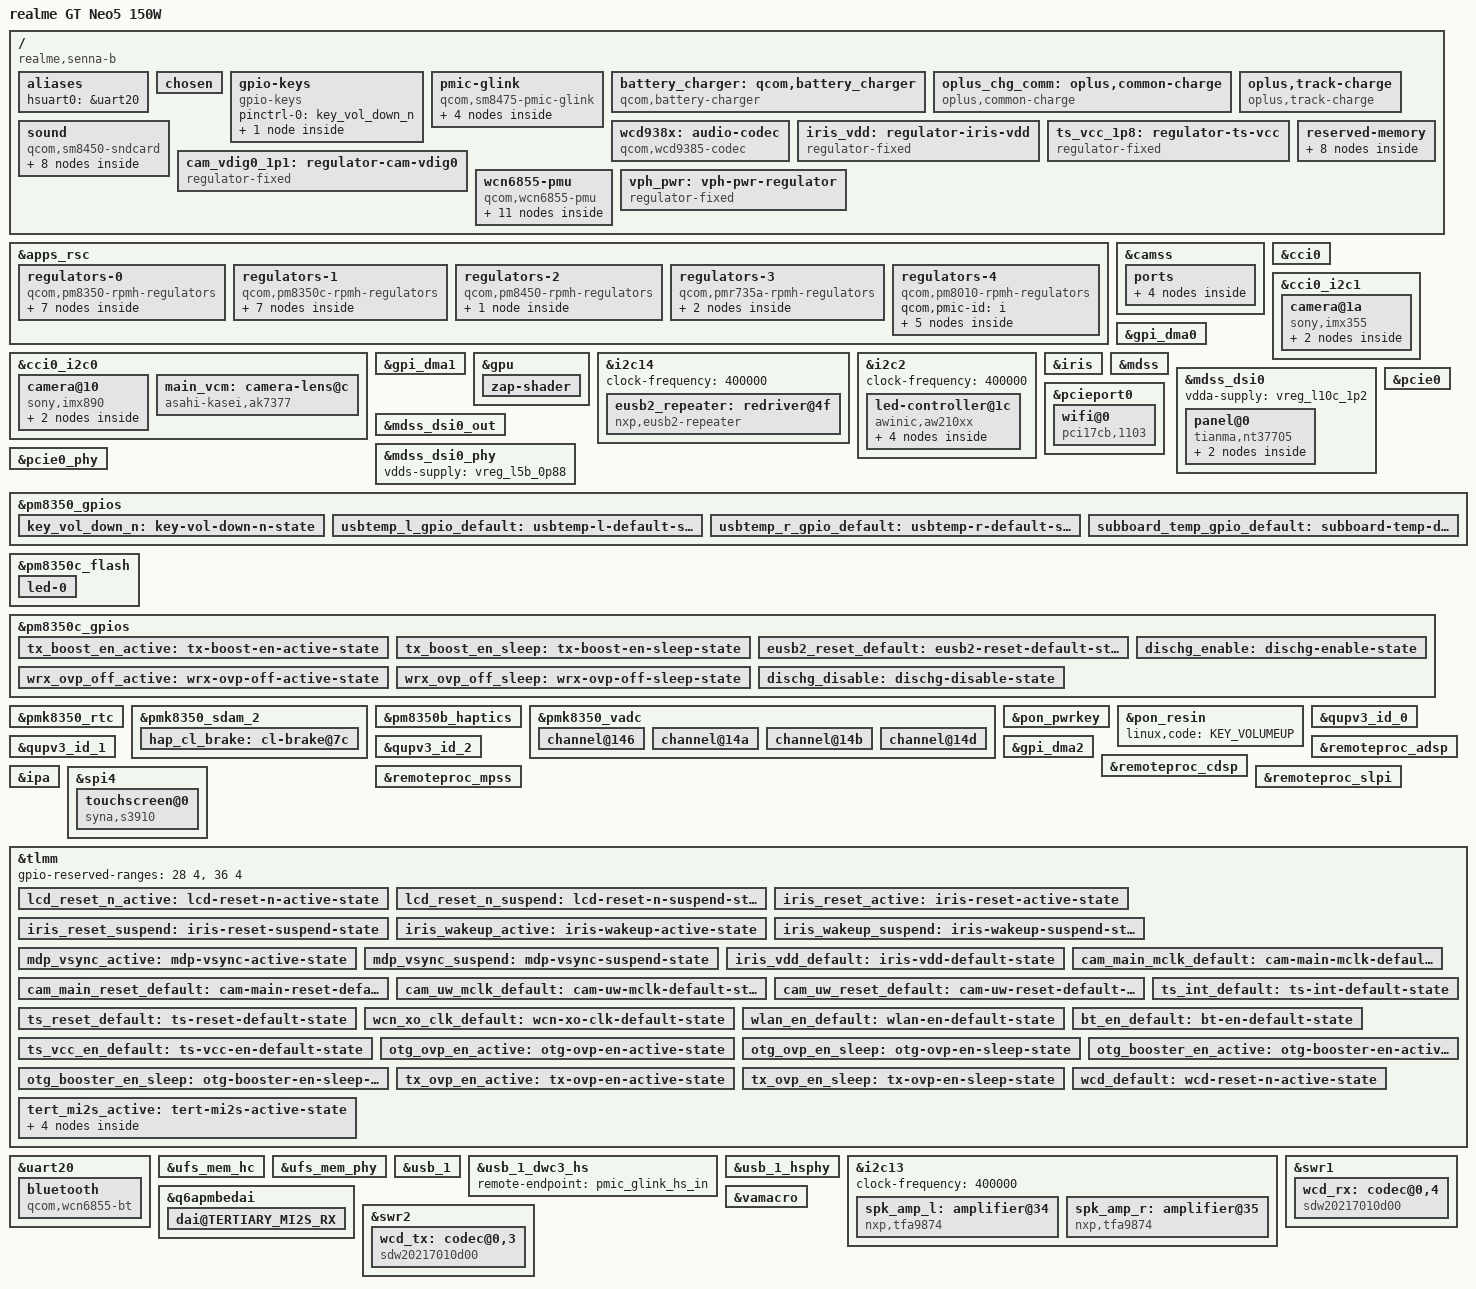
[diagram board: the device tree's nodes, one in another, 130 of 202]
// SPDX-License-Identifier: GPL-2.0-only
/*
 * realme GT Neo5 150W (senna, project 22624)
 *
 * Copyright (c) 2024, The Linux Foundation. All rights reserved.
 * Copyright (c) 2024, Jens Reidel <adrian@travitia.xyz>
 *
 * Based on the senna-b device tree by Marohinmark
 * (github.com/marohinmark/linux-sm8450, branch next). Values (regulators,
 * GPIOs, reserved memory) were checked against the device tree of the
 * running downstream kernel (/sys/firmware/fdt), not guessed. Structure
 * follows sm8475-nothing-pong.dts.
 */
/dts-v1/;

#include <dt-bindings/gpio/gpio.h>
#include <dt-bindings/iio/qcom,spmi-adc7-pm8350.h>
#include <dt-bindings/interrupt-controller/irq.h>
#include <dt-bindings/input/linux-event-codes.h>
#include <dt-bindings/leds/common.h>
#include <dt-bindings/media/video-interfaces.h>
#include <dt-bindings/pinctrl/qcom,pmic-gpio.h>
#include <dt-bindings/regulator/qcom,rpmh-regulator.h>

#include "sm8475.dtsi"
#include "pm8350.dtsi"
#include "pm8350b.dtsi"
#include "pm8350c.dtsi"
#include "pm8450.dtsi"
#include "pmk8350.dtsi"
#include "pmr735a.dtsi"

/delete-node/ &adsp_mem;
/delete-node/ &rmtfs_mem;
/delete-node/ &slpi_mem;
/delete-node/ &video_mem;

/ {
	model = "realme GT Neo5 150W";
	compatible = "realme,senna-b", "qcom,sm8475";
	chassis-type = "handset";

	/*
	 * Booted WITHOUT a valid dtbo: ABL then needs an exact board match
	 * (platform_dt_absolute_match): MTP (0x08), version 1.0, subtype 0,
	 * DDR bits 0 (RAM > 4 GB). Measured on Android: hw_platform=MTP,
	 * platform_version=65536, platform_subtype_id=0, soc_id=530.
	 * No qcom,pmic-id on purpose (ABL parses it in a different layout).
	 */
	qcom,msm-id = <0x212 0x10000>, <0x21c 0x10000>;
	qcom,board-id = <0x10008 0>;

	aliases {
		hsuart0 = &uart20;
	};

	chosen {
		#address-cells = <2>;
		#size-cells = <2>;
		ranges;
	};

	gpio-keys {
		compatible = "gpio-keys";

		pinctrl-0 = <&key_vol_down_n>;
		pinctrl-names = "default";

		key-volume-down {
			label = "Volume Down";
			linux,code = <KEY_VOLUMEDOWN>;
			gpios = <&pm8350_gpios 6 GPIO_ACTIVE_LOW>;
			debounce-interval = <15>;
			linux,can-disable;
			wakeup-source;
		};
	};

	/*
	 * Battery/charger and the USB-C port controller run on the ADSP
	 * (downstream qcom,pmic_glink with qcom,battery_charger, qcom,ucsi and
	 * qcom,altmode). UCSI reports the data role of the port and drives the
	 * DWC3 role switch. USB 2.0 only: the SuperSpeed lanes are not wired up.
	 */
	pmic-glink {
		compatible = "qcom,sm8475-pmic-glink",
			     "qcom,sm8450-pmic-glink",
			     "qcom,pmic-glink";
		#address-cells = <1>;
		#size-cells = <0>;

		connector@0 {
			compatible = "usb-c-connector";
			reg = <0>;
			power-role = "dual";
			data-role = "dual";

			ports {
				#address-cells = <1>;
				#size-cells = <0>;

				port@0 {
					reg = <0>;

					pmic_glink_hs_in: endpoint {
						remote-endpoint = <&usb_1_dwc3_hs>;
					};
				};
			};
		};
	};

	/*
	 * OPLUS charger (oplus_chg v1, out of tree). The OPLUS ADSP charger firmware
	 * keeps charging disabled (BATT_CHG_EN 0, USB ICL 0) until this AP driver
	 * enables it, so it replaces qcom_battmgr on the same pmic_glink service.
	 * Values: oplus-chg-22624.dtsi, identical in the running 5.10 and 6.6 device
	 * trees. Not ported: VOOC/PPS (oplus,adsp-voocphy, the sc8571 charge pumps
	 * and the pps_* strategies) and the nu1619 wireless receiver.
	 */
	battery_charger: qcom,battery_charger {
		compatible = "qcom,battery-charger";
		qcom,thermal-mitigation = <3000000 1500000 1000000 500000>;
		qcom,wireless-fw-name = "idt9415.bin";
		/* OPLUS_CHG_IC_BUCK, first instance */
		oplus,ic_type = <0>;
		oplus,ic_index = <0>;

		oplus,chg_ops = "plat-pmic";
		qcom,smart_charging_screenoff;
		/*
		 * Downstream: <1> (VOOC runs on the ADSP). Off until the AP-side
		 * oplus,adsp-voocphy driver and the sc8571 pumps are ported: with <1>
		 * the driver enables the ADSP VOOC engine without anything on the AP
		 * supervising it.
		 */
		qcom,voocphy_support = <0>;
		qcom,input_current_charger_ma = <2000>;
		qcom,pd_input_current_charger_ma = <2000>;
		qcom,qc_input_current_charger_ma = <2000>;
		qcom,input_current_usb_ma = <500>;
		qcom,input_current_cdp_ma = <1500>;
		qcom,input_current_led_ma = <1200>;
		qcom,input_current_led_ma_high = <1200>;
		qcom,input_current_led_ma_warm = <1500>;
		qcom,input_current_led_ma_normal = <2000>;
		qcom,led_warm_bat_decidegc = <350>;
		qcom,led_high_bat_decidegc = <370>;
		qcom,input_current_camera_ma = <1200>;
		qcom,input_current_vooc_led_ma_high = <2200>;
		qcom,input_current_vooc_led_ma_warm = <3200>;
		qcom,input_current_vooc_led_ma_normal = <3600>;
		qcom,input_current_vooc_ma_normal = <3600>;
		qcom,vooc_temp_bat_normal_decidegc = <350>;
		qcom,input_current_vooc_ma_warm = <3200>;
		qcom,vooc_temp_bat_warm_decidegc = <370>;
		qcom,input_current_vooc_ma_high = <2200>;
		qcom,vooc_temp_bat_hot_decidegc = <440>;
		qcom,charger_current_vooc_ma_normal = <1800>;
		qcom,chg_ctrl_by_calling;
		qcom,input_current_calling_ma = <1500>;
		qcom,overtemp_bat_decidegc = <350>;
		qcom,iterm_disabled = <0>;
		qcom,iterm_ma = <132>;
		qcom,recharge-mv = <100>;
		qcom,batt_capacity_mah = <5000>;
		qcom,removed_bat_decidegc = <390>;
		qcom,cold_bat_decidegc = <200>;
		qcom,temp_cold_vfloat_mv = <4435>;
		qcom,temp_cold_fastchg_current_ma_high = <350>;
		qcom,temp_cold_fastchg_current_ma_low = <200>;
		qcom,temp_cold_fastchg_current_ma = <200>;
		qcom,freeze_bat_decidegc = <100>;
		qcom,temp_freeze_fastchg_current_ma_high = <950>;
		qcom,temp_freeze_fastchg_current_ma_low = <350>;
		qcom,temp_freeze_fastchg_current_ma = <350>;
		qcom,little_cold_bat_decidegc = <0>;
		qcom,temp_little_cold_vfloat_mv = <4435>;
		qcom,temp_little_cold_fastchg_current_ma_high = <1100>;
		qcom,temp_little_cold_fastchg_current_ma_low = <1100>;
		qcom,temp_little_cold_fastchg_current_ma = <1100>;
		qcom,pd_temp_little_cold_fastchg_current_ma_high = <2000>;
		qcom,pd_temp_little_cold_fastchg_current_ma_low = <1500>;
		qcom,qc_temp_little_cold_fastchg_current_ma_high = <2000>;
		qcom,qc_temp_little_cold_fastchg_current_ma_low = <1500>;
		qcom,cool_bat_decidegc = <50>;
		qcom,temp_cool_vfloat_mv = <4435>;
		qcom,temp_cool_fastchg_current_ma_high = <1100>;
		qcom,temp_cool_fastchg_current_ma_low = <1100>;
		qcom,pd_temp_cool_fastchg_current_ma_high = <2000>;
		qcom,pd_temp_cool_fastchg_current_ma_low = <2000>;
		qcom,qc_temp_cool_fastchg_current_ma_high = <2000>;
		qcom,qc_temp_cool_fastchg_current_ma_low = <2000>;
		qcom,little_cool_bat_decidegc = <120>;
		qcom,temp_little_cool_vfloat_mv = <4435>;
		qcom,temp_little_cool_fastchg_current_ma = <1100>;
		qcom,pd_temp_little_cool_fastchg_current_ma = <2000>;
		qcom,qc_temp_little_cool_fastchg_current_ma = <2000>;
		qcom,normal_bat_decidegc = <160>;
		qcom,temp_normal_fastchg_current_ma = <1100>;
		qcom,temp_normal_vfloat_mv = <4435>;
		qcom,pd_temp_normal_fastchg_current_ma = <2000>;
		qcom,qc_temp_normal_fastchg_current_ma = <2000>;
		qcom,warm_bat_decidegc = <450>;
		qcom,temp_warm_vfloat_mv = <4130>;
		qcom,temp_warm_fastchg_current_ma = <1100>;
		qcom,pd_temp_warm_fastchg_current_ma = <1100>;
		qcom,qc_temp_warm_fastchg_current_ma = <1100>;
		qcom,temp_warm_fastchg_current_ma_led_on = <500>;
		qcom,hot_bat_decidegc = <530>;
		qcom,non_standard_vfloat_mv = <3980>;
		qcom,non_standard_fastchg_current_ma = <512>;
		qcom,short_c_bat_cv_mv = <4330>;
		qcom,short_c_bat_vfloat_mv = <3800>;
		qcom,short_c_bat_fastchg_current_ma = <512>;
		qcom,cold_vfloat_sw_limit = <4385>;
		qcom,little_cold_vfloat_sw_limit = <4385>;
		qcom,cool_vfloat_sw_limit = <4385>;
		qcom,little_cool_vfloat_sw_limit = <4385>;
		qcom,normal_vfloat_sw_limit = <4385>;
		qcom,warm_vfloat_sw_limit = <4080>;
		qcom,non_standard_vfloat_sw_limit = <3930>;
		qcom,short_c_bat_vfloat_sw_limit = <3750>;
		qcom,max_chg_time_sec = <69840>;
		qcom,charger_hv_thr = <9900>;
		qcom,charger_recv_thr = <9500>;
		qcom,charger_lv_thr = <3400>;
		qcom,vbatt_full_thr = <4435>;
		qcom,vbatt_hv_thr = <4600>;
		qcom,vfloat_step_mv = <8>;
		qcom,non_standard_vfloat_over_sw_limit = <3990>;
		qcom,cold_vfloat_over_sw_limit = <4445>;
		qcom,little_cold_vfloat_over_sw_limit = <4445>;
		qcom,cool_vfloat_over_sw_limit = <4445>;
		qcom,little_cool_vfloat_over_sw_limit = <4445>;
		qcom,normal_vfloat_over_sw_limit = <4445>;
		qcom,warm_vfloat_over_sw_limit = <4140>;
		qcom,vooc-high-temp = <520>;
		qcom,vooc-normal-high-temp = <430>;
		qcom,vooc-warm-allow-soc = <50>;
		qcom,vooc_batt_over_high_temp = <510>;
		qcom,vooc-warm-allow-vol = <4130>;
		qcom,vbatt_power_off = <3300>;
		qcom,vbatt_soc_1 = <3310>;
		qcom,vooc_project = <9>;
		qcom,vbatt_num = <2>;
		qcom,ffc_support;
		qcom,dual_ffc;
		recharge_after_full;
		qcom,nightstandby_support;
		qcom,normal_vterm_hw_inc = <18>;
		qcom,non_normal_vterm_hw_inc = <18>;
		qcom,ff1_normal_fastchg_ma = <550>;
		qcom,ff1_warm_fastchg_ma = <550>;
		qcom,ffc2_normal_fastchg_ma = <350>;
		qcom,ffc2_temp_warm_decidegc = <350>;
		qcom,ffc2_warm_fastchg_ma = <350>;
		qcom,ffc2_temp_high_decidegc = <400>;
		qcom,ffc2_temp_low_decidegc = <120>;
		qcom,ff1_exit_step_ma = <150>;
		qcom,ff1_warm_exit_step_ma = <150>;
		qcom,ffc2_exit_step_ma = <150>;
		qcom,ffc2_warm_exit_step_ma = <150>;
		qcom,ffc_normal_vfloat_sw_limit = <4445>;
		qcom,ffc_temp_normal_vfloat_mv = <4500>;
		qcom,ffc1_temp_normal_vfloat_mv = <4500>;
		qcom,ffc1_normal_vfloat_over_sw_limit = <4500>;
		qcom,ffc_normal_vfloat_over_sw_limit = <4500>;
		qcom,ffc_warm_vfloat_sw_limit = <4445>;
		qcom,ffc_temp_warm_vfloat_mv = <4500>;
		qcom,ffc_warm_vfloat_over_sw_limit = <4500>;
		qcom,ffc2_normal_vfloat_sw_limit = <4440>;
		qcom,ffc2_temp_normal_vfloat_mv = <4500>;
		qcom,ffc2_normal_vfloat_over_sw_limit = <4500>;
		qcom,ffc2_warm_vfloat_sw_limit = <4435>;
		qcom,ffc2_temp_warm_vfloat_mv = <4500>;
		qcom,ffc2_warm_vfloat_over_sw_limit = <4500>;
		qcom,usbtemp_batt_temp_low = <50>;
		qcom,usbtemp_batt_temp_high = <50>;
		qcom,usbtemp_ntc_temp_low = <57>;
		qcom,usbtemp_ntc_temp_high = <69>;
		qcom,usbtemp_temp_gap_low_with_batt_temp = <7>;
		qcom,usbtemp_temp_gap_high_with_batt_temp = <12>;
		qcom,usbtemp_temp_gap_low_without_batt_temp = <12>;
		qcom,usbtemp_temp_gap_high_without_batt_temp = <24>;
		qcom.usbtemp_rise_fast_temp_low = <3>;
		qcom.usbtemp_rise_fast_temp_high = <3>;
		qcom.usbtemp_rise_fast_temp_count_low = <30>;
		qcom.usbtemp_rise_fast_temp_count_high = <20>;
		qcom,usbtemp_cool_down_ntc_low = <54>;
		qcom,usbtemp_cool_down_ntc_high = <65>;
		qcom,usbtemp_cool_down_gap_low = <12>;
		qcom,usbtemp_cool_down_gap_high = <20>;
		qcom,usbtemp_cool_down_recover_ntc_low = <48>;
		qcom,usbtemp_cool_down_recover_ntc_high = <60>;
		qcom,usbtemp_cool_down_recover_gap_low = <6>;
		qcom,usbtemp_cool_down_recover_gap_high = <15>;
		qcom,default_iterm_ma = <132>;
		qcom,default_temp_normal_fastchg_current_ma = <1100>;
		qcom,default_normal_vfloat_sw_limit = <4385>;
		qcom,default_temp_normal_vfloat_mv = <4435>;
		qcom,default_normal_vfloat_over_sw_limit = <4445>;
		qcom,default_temp_little_cool_fastchg_current_ma = <1100>;
		qcom,default_little_cool_vfloat_sw_limit = <4385>;
		qcom,default_temp_little_cool_vfloat_mv = <4435>;
		qcom,default_little_cool_vfloat_over_sw_limit = <4445>;
		qcom,fg_info_package_read_support;
		qcom,check_batt_full_by_sw;
		qcom,external_gauge;
		qcom,chg_ctrl_by_lcd;
		qcom,chg_ctrl_by_vooc;
		qcom,chg_ctrl_by_camera;
		qcom,sw_vfloat_over_protect_enable;
		qcom,usbtemp_batttemp_gap = <12>;
		qcom,usbtemp_change_gap;
		oplus,smooth_switch_v2;
		oplus,reserve_chg_soc = <2>;
		oplus,reserve_dis_soc = <2>;
		qcom,smart_chg_soh_support;
		oplus,aging_ffc_version = <1>;
		oplus,quick_mode_gain_support;
		qcom,support_usbtemp_protect_v2;
		qcom,vbatt_pdqc_to_9v_thr = <5000>;
		qcom,vooc_show_ui_soc_decimal;
		qcom,ui_soc_decimal_speedmin = <20>;
		qcom,otg_scheme = <0>;
		qcom,otg_boost_src = <0>;

		qcom,dischg-gpio = <&pm8350c_gpios 9 GPIO_ACTIVE_HIGH>;
		qcom,otg-booster-en-gpio = <&tlmm 64 GPIO_ACTIVE_HIGH>;
		qcom,otg-ovp-en-gpio = <&tlmm 57 GPIO_ACTIVE_HIGH>;
		qcom,tx_ovp_en-gpio = <&tlmm 126 GPIO_ACTIVE_HIGH>;
		qcom,tx_boost_en-gpio = <&pm8350c_gpios 4 GPIO_ACTIVE_HIGH>;
		qcom,wrx_ovp_off-gpio = <&pm8350c_gpios 8 GPIO_ACTIVE_HIGH>;

		io-channels = <&pmk8350_vadc PM8350_ADC7_GPIO1_100K_PU(1)>,
			      <&pmk8350_vadc PM8350_ADC7_GPIO2_100K_PU(1)>,
			      <&pmk8350_vadc PM8350_ADC7_GPIO4_100K_PU(1)>;
		io-channel-names = "usb_temp_adc",
				   "usb_supplementary_temp_adc",
				   "subboard_temp_adc";

		/* the driver selects these by name, none of them is "default" */
		pinctrl-0 = <&dischg_enable>;
		pinctrl-1 = <&dischg_disable>;
		pinctrl-2 = <&otg_booster_en_active>;
		pinctrl-3 = <&otg_booster_en_sleep>;
		pinctrl-4 = <&otg_ovp_en_active>;
		pinctrl-5 = <&otg_ovp_en_sleep>;
		pinctrl-6 = <&usbtemp_l_gpio_default>;
		pinctrl-7 = <&usbtemp_r_gpio_default>;
		pinctrl-8 = <&tx_ovp_en_active>;
		pinctrl-9 = <&tx_ovp_en_sleep>;
		pinctrl-10 = <&tx_boost_en_active>;
		pinctrl-11 = <&tx_boost_en_sleep>;
		pinctrl-12 = <&wrx_ovp_off_active>;
		pinctrl-13 = <&wrx_ovp_off_sleep>;
		pinctrl-14 = <&subboard_temp_gpio_default>;
		pinctrl-names = "dischg_enable", "dischg_disable",
				"otg_booster_en_active", "otg_booster_en_sleep",
				"otg_ovp_en_active", "otg_ovp_en_sleep",
				"usbtemp_l_gpio_default", "usbtemp_r_gpio_default",
				"tx_ovp_en_active", "tx_ovp_en_sleep",
				"tx_boost_en_active", "tx_boost_en_sleep",
				"wrx_ovp_off_active", "wrx_ovp_off_sleep",
				"subboard_temp_gpio_default";
	};

	oplus_chg_comm: oplus,common-charge {
		compatible = "oplus,common-charge";

		io-channels = <&pmk8350_vadc PM8350_ADC7_AMUX_THM3_100K_PU(1)>;
		io-channel-names = "pm8350_hot_pocket_therm";
		oplus,skin_temp_chan = "pm8350_hot_pocket_therm";

		oplus,check-batt-full-by-sw;
		oplus,fv-offset-voltage-mv = <50>;
		oplus,sw-iterm-ma = <115>;
		oplus,full-count-sw-num = <2>;
		oplus,batt-uv-mv = <2500>;
		oplus,batt-ov-mv = <4950>;
		oplus,batt-oc-ma = <6500>;
		oplus,batt-ovd-mv = <1000>;
		oplus,batt-curr-limit-thr-mv = <5000>;

		oplus,batt-them-thr = <(-100) 0 50 120 160 400 440 530>;
		oplus,vbatmax-mv = <0 4435 4435 4435 4435 4435 4435 4130 0>;
		oplus,ffc-temp-thr = <120 350 400>;
		oplus,usb-ffc-step-max = <1>;
		oplus,usb-ffc-fv-mv = <4500>;
		oplus,usb-ffc-fv-cutoff-mv = <4445>;
		oplus,usb-ffc-fcc-ma = <350 400>;
		oplus,usb-ffc-fcc-cutoff-ma = <300 350>;
		oplus,wls-ffc-step-max = <2>;
		oplus,wls-ffc-fv-mv = <4500 4500>;
		oplus,wls-ffc-fv-cutoff-mv = <4445 4435>;
		oplus,wls-ffc-icl-ma = <800 800 550 550>;
		oplus,wls-ffc-fcc-ma = <550 550 350 350>;
		oplus,wls-ffc-fcc-cutoff-ma = <400 400 200 200>;
		oplus,wls-vbatdet-mv = <0 4135 4235 4335 4335 4335 4335 4030 0>;
	};

	oplus,track-charge {
		compatible = "oplus,track-charge";
		track,fast_chg_break_t_thd = <1000>;
		track,general_chg_break_t_thd = <200>;
		track,voocphy_type = <1>;
		track,wired_max_power = <150000>;
		track,wired_fast_chg_scheme = <0>;
	};

	/* Speakers: 2x TFA9874 on tertiary MI2S (downstream rx-lines 0x2 = SD1) */
	sound {
		compatible = "qcom,sm8450-sndcard";
		model = "SM8475-realme-senna";
		/* mic bias assignment from the 5.10 qcom,audio-routing (AMIC5 on bias 3) */
		audio-routing = "AMIC1", "MIC BIAS1",
				"AMIC2", "MIC BIAS2",
				"AMIC4", "MIC BIAS4",
				"AMIC5", "MIC BIAS3",
				"TX SWR_INPUT0", "ADC1_OUTPUT",
				"TX SWR_INPUT1", "ADC2_OUTPUT",
				"TX SWR_INPUT0", "ADC3_OUTPUT",
				"TX SWR_INPUT1", "ADC4_OUTPUT";

		pinctrl-0 = <&tert_mi2s_active>;
		pinctrl-names = "default";

		speaker-dai-link {
			link-name = "Speaker Playback";

			cpu {
				sound-dai = <&q6apmbedai TERTIARY_MI2S_RX>;
			};

			codec {
				sound-dai = <&spk_amp_l>, <&spk_amp_r>;
			};

			platform {
				sound-dai = <&q6apm>;
			};
		};

		mic-dai-link {
			link-name = "WCD Capture";

			cpu {
				sound-dai = <&q6apmbedai TX_CODEC_DMA_TX_3>;
			};

			codec {
				sound-dai = <&wcd938x 1>, <&swr2 0>, <&txmacro 0>;
			};

			platform {
				sound-dai = <&q6apm>;
			};
		};
	};

	/*
	 * WCD9385: analog microphones only (speakers/earpiece are the TFA9874s).
	 * Values from the 5.10 DT (senna-live.dtb, wcd938x-codec): micbias1-3
	 * 2.7 V, micbias4 1.8 V, rx/tx/io/buck from pm8350 s10, mic bias from bob,
	 * reset on tlmm 43.
	 */
	wcd938x: audio-codec {
		compatible = "qcom,wcd9385-codec";

		pinctrl-0 = <&wcd_default>;
		pinctrl-names = "default";

		qcom,micbias1-microvolt = <2700000>;
		qcom,micbias2-microvolt = <2700000>;
		qcom,micbias3-microvolt = <2700000>;
		qcom,micbias4-microvolt = <1800000>;
		/* no 3.5 mm jack on senna; HDK values only to satisfy the parser */
		qcom,mbhc-buttons-vthreshold-microvolt = <75000 150000 237000 500000 500000 500000 500000 500000>;
		qcom,mbhc-headset-vthreshold-microvolt = <1700000>;
		qcom,mbhc-headphone-vthreshold-microvolt = <50000>;
		qcom,rx-device = <&wcd_rx>;
		qcom,tx-device = <&wcd_tx>;

		reset-gpios = <&tlmm 43 GPIO_ACTIVE_LOW>;

		vdd-buck-supply = <&vreg_s10b_1p8>;
		vdd-rxtx-supply = <&vreg_s10b_1p8>;
		vdd-io-supply = <&vreg_s10b_1p8>;
		vdd-mic-bias-supply = <&vreg_bob>;

		#sound-dai-cells = <1>;
	};

	/* Pixelworks Iris 5, powered from tlmm 182 ("qcom,iris-vdd-gpio") */
	iris_vdd: regulator-iris-vdd {
		compatible = "regulator-fixed";
		regulator-name = "iris_vdd";
		regulator-min-microvolt = <1800000>;
		regulator-max-microvolt = <1800000>;

		gpio = <&tlmm 182 GPIO_ACTIVE_HIGH>;
		enable-active-high;
		/* downstream iris_power_on(): 5 ms after enabling vdd */
		startup-delay-us = <5000>;
		/* left on by the bootloader together with the panel */
		regulator-boot-on;

		pinctrl-0 = <&iris_vdd_default>;
		pinctrl-names = "default";
	};

	/*
	 * Touch controller 1.8 V: downstream "enable1v8_gpio" (tlmm 97, driven
	 * high to enable) in front of vcc_1v8 = PM8450 L4.
	 */
	ts_vcc_1p8: regulator-ts-vcc {
		compatible = "regulator-fixed";
		regulator-name = "ts_vcc_1p8";
		regulator-min-microvolt = <1800000>;
		regulator-max-microvolt = <1800000>;

		gpio = <&tlmm 97 GPIO_ACTIVE_HIGH>;
		enable-active-high;
		vin-supply = <&vreg_l4h_1p8>;

		pinctrl-0 = <&ts_vcc_en_default>;
		pinctrl-names = "default";
	};

	/*
	 * Camera vdig LDO (downstream camera_vdig0_ldo, 1.104 V from S12B).
	 * Its enable is the same tlmm 97 as the touch 1.8 V switch above; the
	 * regulator core shares the GPIO between the two.
	 */
	cam_vdig0_1p1: regulator-cam-vdig0 {
		compatible = "regulator-fixed";
		regulator-name = "cam_vdig0_1p1";
		regulator-min-microvolt = <1104000>;
		regulator-max-microvolt = <1104000>;
		regulator-enable-ramp-delay = <135>;

		gpio = <&tlmm 97 GPIO_ACTIVE_HIGH>;
		enable-active-high;
		vin-supply = <&vreg_s12b_1p25>;
	};

	reserved-memory {
		ramoops@85200000 {
			compatible = "ramoops";
			reg = <0x0 0x85200000 0x0 0x400000>;

			record-size = <0x200000>;
			pmsg-size = <0x200000>;
			console-size = <0x200000>;
			no-map;
		};

		adsp_mem: memory@85700000 {
			reg = <0x0 0x85700000 0x0 0x2800000>;
			no-map;
		};

		/* starts 1 MiB lower than on sm8450.dtsi */
		slpi_mem: memory@87f00000 {
			reg = <0x0 0x87f00000 0x0 0x1a00000>;
			no-map;
		};

		video_mem: memory@9fd00000 {
			reg = <0x0 0x9fd00000 0x0 0x700000>;
			no-map;
		};

		/* OPLUS device_info / bootloader log, kept as on downstream */
		device_info_mem: memory@a4f00000 {
			reg = <0x0 0xa4f00000 0x0 0x8000>;
		};

		bootloader_log_mem: memory@a7605000 {
			reg = <0x0 0xa7605000 0x0 0x8000>;
		};

		splash_region@b8000000 {
			reg = <0x0 0xb8000000 0x0 0x2b00000>;
			no-map;
		};

		/* downstream allocates it dynamically; this is where it landed */
		rmtfs_mem: memory@fd100000 {
			compatible = "qcom,rmtfs-mem";
			reg = <0x0 0xfd100000 0x0 0x280000>;
			no-map;

			qcom,client-id = <1>;
			qcom,vmid = <QCOM_SCM_VMID_MSS_MSA>;
		};
	};

	/*
	 * QCA6490 (WCN6855 family) WLAN/BT, same wiring as on the Nothing
	 * Phone (2). Values from the downstream cnss-qca6490/bt_qca6490 nodes:
	 * wlan-en tlmm 80, bt-en tlmm 81, vdd-wlan-io S10B, -aon S2E, -dig
	 * S11B, -rfa1 S1C, -rfa2 S12B; PCIe0, BT on QUP SE20 (uart20).
	 */
	wcn6855-pmu {
		compatible = "qcom,wcn6855-pmu";

		pinctrl-0 = <&bt_en_default>;
		pinctrl-names = "default";

		wlan-enable-gpios = <&tlmm 80 GPIO_ACTIVE_HIGH>;
		bt-enable-gpios = <&tlmm 81 GPIO_ACTIVE_HIGH>;

		vddio-supply = <&vreg_s10b_1p8>;
		vddaon-supply = <&vreg_s2e_0p85>;
		vddpmu-supply = <&vreg_s11b_0p95>;
		vddrfa0p95-supply = <&vreg_s11b_0p95>;
		vddrfa1p3-supply = <&vreg_s12b_1p25>;
		vddrfa1p9-supply = <&vreg_s1c_1p88>;
		vddpcie1p3-supply = <&vreg_s12b_1p25>;
		vddpcie1p9-supply = <&vreg_s1c_1p88>;

		regulators {
			vreg_pmu_rfa_cmn_0p8: ldo0 {
				regulator-name = "vreg_pmu_rfa_cmn_0p8";
			};

			vreg_pmu_aon_0p8: ldo1 {
				regulator-name = "vreg_pmu_aon_0p8";
			};

			vreg_pmu_wlcx_0p8: ldo2 {
				regulator-name = "vreg_pmu_wlcx_0p8";
			};

			vreg_pmu_wlmx_0p8: ldo3 {
				regulator-name = "vreg_pmu_wlmx_0p8";
			};

			vreg_pmu_btcmx_0p8: ldo4 {
				regulator-name = "vreg_pmu_btcmx_0p8";
			};

			vreg_pmu_pcie_1p8: ldo5 {
				regulator-name = "vreg_pmu_pcie_1p8";
			};

			vreg_pmu_pcie_0p9: ldo6 {
				regulator-name = "vreg_pmu_pcie_0p9";
			};

			vreg_pmu_rfa_0p8: ldo7 {
				regulator-name = "vreg_pmu_rfa_0p8";
			};

			vreg_pmu_rfa_1p2: ldo8 {
				regulator-name = "vreg_pmu_rfa_1p2";
			};

			vreg_pmu_rfa_1p7: ldo9 {
				regulator-name = "vreg_pmu_rfa_1p7";
			};
		};
	};

	vph_pwr: vph-pwr-regulator {
		compatible = "regulator-fixed";
		regulator-name = "vph_pwr";
		regulator-min-microvolt = <3700000>;
		regulator-max-microvolt = <3700000>;

		regulator-always-on;
		regulator-boot-on;
	};
};

/*
 * Only regulators that have a consumer here (plus their parents) are
 * described. Minimum voltages are the downstream qcom,init-voltage values:
 * the regulator core votes the minimum at probe, exactly like downstream.
 * PM8350B L1 (panel "extvdd", 1.2 V) has no mainline rpmh description; it
 * stays as the bootloader left it.
 */
&apps_rsc {
	regulators-0 {
		compatible = "qcom,pm8350-rpmh-regulators";
		qcom,pmic-id = "b";

		vdd-s10-supply = <&vph_pwr>;
		vdd-s11-supply = <&vph_pwr>;
		vdd-s12-supply = <&vph_pwr>;

		vdd-l2-l7-supply = <&vreg_bob>;
		vdd-l3-l5-supply = <&vreg_s11b_0p95>;
		vdd-l6-l9-l10-supply = <&vreg_s12b_1p25>;

		vreg_s10b_1p8: smps10 {
			regulator-name = "vreg_s10b_1p8";
			regulator-min-microvolt = <1800000>;
			regulator-max-microvolt = <1800000>;
		};

		vreg_s11b_0p95: smps11 {
			regulator-name = "vreg_s11b_0p95";
			regulator-min-microvolt = <952000>;
			regulator-max-microvolt = <1170000>;
		};

		vreg_s12b_1p25: smps12 {
			regulator-name = "vreg_s12b_1p25";
			regulator-min-microvolt = <1256000>;
			regulator-max-microvolt = <2040000>;
		};

		vreg_l2b_3p07: ldo2 {
			regulator-name = "vreg_l2b_3p07";
			regulator-min-microvolt = <3072000>;
			regulator-max-microvolt = <3300000>;
			regulator-initial-mode = <RPMH_REGULATOR_MODE_HPM>;
		};

		vreg_l5b_0p88: ldo5 {
			regulator-name = "vreg_l5b_0p88";
			regulator-min-microvolt = <880000>;
			regulator-max-microvolt = <958000>;
			regulator-initial-mode = <RPMH_REGULATOR_MODE_HPM>;
		};

		vreg_l7b_2p5: ldo7 {
			regulator-name = "vreg_l7b_2p5";
			regulator-min-microvolt = <2504000>;
			regulator-max-microvolt = <2504000>;
			regulator-initial-mode = <RPMH_REGULATOR_MODE_HPM>;
		};

		vreg_l9b_1p2: ldo9 {
			regulator-name = "vreg_l9b_1p2";
			regulator-min-microvolt = <1200000>;
			regulator-max-microvolt = <1304000>;
			regulator-initial-mode = <RPMH_REGULATOR_MODE_HPM>;
		};
	};

	regulators-1 {
		compatible = "qcom,pm8350c-rpmh-regulators";
		qcom,pmic-id = "c";

		vdd-s1-supply = <&vph_pwr>;

		vdd-l1-l12-supply = <&vreg_s1c_1p88>;
		vdd-l3-l4-l5-l7-l13-supply = <&vreg_bob>;
		vdd-l10-supply = <&vreg_s12b_1p25>;

		vdd-bob-supply = <&vph_pwr>;

		vreg_s1c_1p88: smps1 {
			regulator-name = "vreg_s1c_1p88";
			regulator-min-microvolt = <1880000>;
			regulator-max-microvolt = <2024000>;
		};

		/* camera vio (downstream L2C) */
		vreg_l2c_1p8: ldo2 {
			regulator-name = "vreg_l2c_1p8";
			regulator-min-microvolt = <1800000>;
			regulator-max-microvolt = <1980000>;
			regulator-initial-mode = <RPMH_REGULATOR_MODE_HPM>;
		};

		/* touch vdd_2v8; downstream vdd_2v8_volt = 3008000 */
		vreg_l3c_3p0: ldo3 {
			regulator-name = "vreg_l3c_3p0";
			regulator-min-microvolt = <3008000>;
			regulator-max-microvolt = <3008000>;
			regulator-initial-mode = <RPMH_REGULATOR_MODE_HPM>;
		};

		vreg_l10c_1p2: ldo10 {
			regulator-name = "vreg_l10c_1p2";
			regulator-min-microvolt = <1200000>;
			regulator-max-microvolt = <1304000>;
			regulator-initial-mode = <RPMH_REGULATOR_MODE_HPM>;
		};

		/* panel vddio, display only */
		vreg_l12c_1p8: ldo12 {
			regulator-name = "vreg_l12c_1p8";
			regulator-min-microvolt = <1800000>;
			regulator-max-microvolt = <1800000>;
			regulator-initial-mode = <RPMH_REGULATOR_MODE_HPM>;
		};

		/* panel vci, display only; the panel needs 3.0 V */
		vreg_l13c_3p0: ldo13 {
			regulator-name = "vreg_l13c_3p0";
			regulator-min-microvolt = <3000000>;
			regulator-max-microvolt = <3000000>;
			regulator-initial-mode = <RPMH_REGULATOR_MODE_HPM>;
		};

		vreg_bob: bob {
			regulator-name = "vreg_bob";
			regulator-min-microvolt = <3008000>;
			regulator-max-microvolt = <3960000>;
			regulator-initial-mode = <RPMH_REGULATOR_MODE_AUTO>;
		};
	};

	regulators-2 {
		compatible = "qcom,pm8450-rpmh-regulators";
		qcom,pmic-id = "h";

		vdd-l4-supply = <&vreg_bob>;

		/* touch vcc_1v8 */
		vreg_l4h_1p8: ldo4 {
			regulator-name = "vreg_l4h_1p8";
			regulator-min-microvolt = <1800000>;
			regulator-max-microvolt = <1800000>;
			regulator-initial-mode = <RPMH_REGULATOR_MODE_HPM>;
		};
	};

	regulators-3 {
		compatible = "qcom,pmr735a-rpmh-regulators";
		qcom,pmic-id = "e";

		vdd-s2-supply = <&vph_pwr>;
		vdd-l7-bob-supply = <&vreg_bob>;

		/*
		 * WLAN/BT aon. Always on so the chip is powered when the PCIe
		 * link is trained, before the pwrseq module takes over.
		 */
		vreg_s2e_0p85: smps2 {
			regulator-name = "vreg_s2e_0p85";
			regulator-min-microvolt = <500000>;
			regulator-max-microvolt = <1040000>;
			regulator-always-on;
		};

		/*
		 * WLAN/BT antenna switch (downstream wlan-ant-switch-supply,
		 * bt-vdd-asd-supply, 2.8 V). No mainline consumer, keep it on.
		 */
		vreg_l7e_2p8: ldo7 {
			regulator-name = "vreg_l7e_2p8";
			regulator-min-microvolt = <2800000>;
			regulator-max-microvolt = <2800000>;
			regulator-always-on;
		};
	};

	/* PM8010 camera PMIC (downstream ldoi*) */
	regulators-4 {
		compatible = "qcom,pm8010-rpmh-regulators";
		qcom,pmic-id = "i";

		/* main camera vdig (downstream L1I) */
		vreg_l1i_1p1: ldo1 {
			regulator-name = "vreg_l1i_1p1";
			regulator-min-microvolt = <1104000>;
			regulator-max-microvolt = <1104000>;
			regulator-initial-mode = <RPMH_REGULATOR_MODE_HPM>;
		};

		/* main camera vana (downstream L3I) */
		vreg_l3i_2p8: ldo3 {
			regulator-name = "vreg_l3i_2p8";
			regulator-min-microvolt = <2800000>;
			regulator-max-microvolt = <2800000>;
			regulator-initial-mode = <RPMH_REGULATOR_MODE_HPM>;
		};

		/* main camera module supply (downstream L5I, cam_v_custom1) */
		vreg_l5i_1p8: ldo5 {
			regulator-name = "vreg_l5i_1p8";
			regulator-min-microvolt = <1800000>;
			regulator-max-microvolt = <1800000>;
			regulator-initial-mode = <RPMH_REGULATOR_MODE_HPM>;
		};

		/* ultra wide camera vana (downstream L4I) */
		vreg_l4i_2p8: ldo4 {
			regulator-name = "vreg_l4i_2p8";
			regulator-min-microvolt = <2800000>;
			regulator-max-microvolt = <2800000>;
			regulator-initial-mode = <RPMH_REGULATOR_MODE_HPM>;
		};

		/* main camera autofocus actuator (downstream L6I, cam_vaf) */
		vreg_l6i_2p8: ldo6 {
			regulator-name = "vreg_l6i_2p8";
			regulator-min-microvolt = <2800000>;
			regulator-max-microvolt = <2800000>;
			regulator-initial-mode = <RPMH_REGULATOR_MODE_HPM>;
		};
	};
};

&camss {
	/* downstream csiphy csi-vdd-0p9 = pm8350_l5, csi-vdd-1p2 = pm8350c_l10 */
	vdda-phy-supply = <&vreg_l5b_0p88>;
	vdda-pll-supply = <&vreg_l10c_1p2>;

	status = "okay";

	ports {
		port@1 {
			csiphy1_ep: endpoint {
				data-lanes = <0 1 2 3>;
				bus-type = <MEDIA_BUS_TYPE_CSI2_DPHY>;
				remote-endpoint = <&cam_uw_ep>;
			};
		};

		port@3 {
			csiphy3_ep: endpoint {
				data-lanes = <0 1 2>;
				bus-type = <MEDIA_BUS_TYPE_CSI2_CPHY>;
				remote-endpoint = <&cam_main_ep>;
			};
		};
	};
};

&cci0 {
	status = "okay";
};

/* downstream cam-sensor0 (sunny/qtech imx890): CCI0 master 0, CSIPHY3, MCLK1 */
&cci0_i2c0 {
	/* chip id 0x0890 answers at 0x10; module EEPROMs at 0x50 and 0x58, AF VCM at 0x0c */
	camera@10 {
		compatible = "sony,imx890";
		reg = <0x10>;

		vio-supply = <&vreg_l2c_1p8>;
		vana-supply = <&vreg_l3i_2p8>;
		vdig-supply = <&vreg_l1i_1p1>;
		vcustom-supply = <&vreg_l5i_1p8>;

		clocks = <&camcc CAM_CC_MCLK1_CLK>;
		assigned-clocks = <&camcc CAM_CC_MCLK1_CLK>;
		assigned-clock-rates = <19200000>;

		reset-gpios = <&tlmm 120 GPIO_ACTIVE_LOW>;

		pinctrl-0 = <&cam_main_mclk_default>, <&cam_main_reset_default>;
		pinctrl-names = "default";

		/* downstream sensor-position: roll 90, yaw 180 like the ultra wide */
		orientation = <1>;
		rotation = <270>;
		lens-focus = <&main_vcm>;

		port {
			/* sensor module: 3 C-PHY trios (0x0114 = 2, 0x0111 = 3) */
			cam_main_ep: endpoint {
				data-lanes = <1 2 3>;
				bus-type = <MEDIA_BUS_TYPE_CSI2_CPHY>;
				link-frequencies = /bits/ 64 <1238400000>;
				remote-endpoint = <&csiphy3_ep>;
			};
		};
	};

	/* qtech module autofocus VCM (stock imx890_ak7377) */
	main_vcm: camera-lens@c {
		compatible = "asahi-kasei,ak7377";
		reg = <0x0c>;
		vdd-supply = <&vreg_l6i_2p8>;
		vio-supply = <&vreg_l2c_1p8>;
	};
};

/* downstream cam-sensor1 (sunny imx355): CCI0 master 1, CSIPHY1, MCLK2 */
&cci0_i2c1 {
	camera@1a {
		compatible = "sony,imx355";
		reg = <0x1a>;

		avdd-supply = <&vreg_l4i_2p8>;
		dvdd-supply = <&cam_vdig0_1p1>;
		dovdd-supply = <&vreg_l2c_1p8>;

		clocks = <&camcc CAM_CC_MCLK2_CLK>;
		assigned-clocks = <&camcc CAM_CC_MCLK2_CLK>;
		assigned-clock-rates = <19200000>;

		reset-gpios = <&tlmm 24 GPIO_ACTIVE_LOW>;

		pinctrl-0 = <&cam_uw_mclk_default>, <&cam_uw_reset_default>;
		pinctrl-names = "default";

		/*
		 * downstream sensor-position: roll 90, yaw 180 (back). The
		 * image is upside down with rotation 90, so it is 270 here.
		 */
		orientation = <1>;
		rotation = <270>;

		port {
			/* sensor module: 4 lanes (0x0114 = 3), laneAssign 0x3210, D-PHY */
			cam_uw_ep: endpoint {
				data-lanes = <1 2 3 4>;
				link-frequencies = /bits/ 64 <360000000>;
				remote-endpoint = <&csiphy1_ep>;
			};
		};
	};
};

&gpi_dma0 {
	status = "okay";
};

&gpi_dma1 {
	status = "okay";
};

&gpu {
	status = "okay";

	zap-shader {
		/*
		 * Split image from the ROM vendor partition (/vendor/firmware),
		 * the one kgsl loads (zap_name "a730_zap.mdt"). The a730_zap.mbn
		 * there is a different build (last segment 3896 vs 3416 bytes),
		 * PAS init returned -EINVAL for it.
		 */
		firmware-name = "qcom/sm8475/realme/senna/a730_zap.mdt";
	};
};

&i2c14 {
	clock-frequency = <400000>;
	status = "okay";

	/* downstream "eusb2_repeater_oplus@4f" */
	eusb2_repeater: redriver@4f {
		compatible = "nxp,eusb2-repeater";
		reg = <0x4f>;

		vdd18-supply = <&vreg_s10b_1p8>;
		vdd3-supply = <&vreg_l2b_3p07>;

		reset-gpio = <&pm8350c_gpios 7 GPIO_ACTIVE_HIGH>;
		pinctrl-0 = <&eusb2_reset_default>;
		pinctrl-names = "default";

		qcom,param-override-seq = <0x63 0x08 0x00 0x07 0x43 0x06 0x03 0x0a>;
		qcom,param-override-seq-host = <0x62 0x08 0x00 0x07 0x50 0x06 0x03 0x0a>;

		#phy-cells = <0>;
	};
};

/* downstream qupv3_se2_i2c: aw210xx_led@1C (oplus_breathing/senna_breathing_leds.dtsi) */
&i2c2 {
	clock-frequency = <400000>;
	status = "okay";

	led-controller@1c {
		compatible = "awinic,aw210xx";
		reg = <0x1c>;

		enable-gpios = <&tlmm 155 GPIO_ACTIVE_HIGH>;
		vbled-gpios = <&tlmm 153 GPIO_ACTIVE_HIGH>;
		awinic,global-current = <0xcc>;

		/* channels as used by the downstream driver: SL09..SL11 = R, G, B */
		multi-led {
			color = <LED_COLOR_ID_RGB>;
			function = LED_FUNCTION_STATUS;
			#address-cells = <1>;
			#size-cells = <0>;

			led@9 {
				reg = <9>;
				color = <LED_COLOR_ID_RED>;
			};

			led@a {
				reg = <10>;
				color = <LED_COLOR_ID_GREEN>;
			};

			led@b {
				reg = <11>;
				color = <LED_COLOR_ID_BLUE>;
			};
		};
	};
};

&iris {
	firmware-name = "qcom/sm8475/realme/senna/vpu20_4v.mbn";

	status = "okay";
};

&mdss {
	status = "okay";
};

&mdss_dsi0 {
	vdda-supply = <&vreg_l10c_1p2>;
	status = "okay";

	panel@0 {
		compatible = "tianma,nt37705";
		reg = <0>;

		reset-gpios = <&tlmm 3 GPIO_ACTIVE_LOW>;

		vddio-supply = <&vreg_l12c_1p8>;
		vci-supply = <&vreg_l13c_3p0>;

		/* Iris 5 sits between DSI and the panel, used in bypass */
		iris-vdd-supply = <&iris_vdd>;
		iris-reset-gpios = <&tlmm 44 GPIO_ACTIVE_LOW>;
		iris-wakeup-gpios = <&tlmm 54 GPIO_ACTIVE_HIGH>;

		pinctrl-0 = <&lcd_reset_n_active>, <&mdp_vsync_active>,
			    <&iris_reset_active>, <&iris_wakeup_active>;
		pinctrl-1 = <&lcd_reset_n_suspend>, <&mdp_vsync_suspend>,
			    <&iris_reset_suspend>, <&iris_wakeup_suspend>;
		pinctrl-names = "default", "sleep";

		port {
			panel_in: endpoint {
				remote-endpoint = <&mdss_dsi0_out>;
			};
		};
	};
};

&mdss_dsi0_out {
	remote-endpoint = <&panel_in>;
	data-lanes = <0 1 2 3>;
};

&mdss_dsi0_phy {
	vdds-supply = <&vreg_l5b_0p88>;
	status = "okay";
};

/*
 * pwrseq-qcom-wcn takes wlan-enable GPIOD_ASIS and expects it to be high
 * before the PCIe link is trained (driver FIXME). ABL leaves it low and the
 * pwrseq module only probes seconds after link training, so drive it high
 * from the controller's own pin state, applied before link training.
 */
&pcie0 {
	pinctrl-0 = <&pcie0_default_state>, <&wcn_xo_clk_default>, <&wlan_en_default>;
	pinctrl-names = "default";

	/*
	 * sm8475.dtsi has perst-gpio ACTIVE_HIGH, which keeps the endpoint
	 * in reset (measured: gpio94 out low after "deassert"). PERST# is
	 * active low, as in sm8450.dtsi.
	 */
	/delete-property/ perst-gpio;
	perst-gpios = <&tlmm 94 GPIO_ACTIVE_LOW>;

	status = "okay";
};

&pcieport0 {
	wifi@0 {
		compatible = "pci17cb,1103";
		reg = <0x10000 0x0 0x0 0x0 0x0>;

		vddrfacmn-supply = <&vreg_pmu_rfa_cmn_0p8>;
		vddaon-supply = <&vreg_pmu_aon_0p8>;
		vddwlcx-supply = <&vreg_pmu_wlcx_0p8>;
		vddwlmx-supply = <&vreg_pmu_wlmx_0p8>;
		vddpcie1p8-supply = <&vreg_pmu_pcie_1p8>;
		vddpcie0p9-supply = <&vreg_pmu_pcie_0p9>;
		vddrfa0p8-supply = <&vreg_pmu_rfa_0p8>;
		vddrfa1p2-supply = <&vreg_pmu_rfa_1p2>;
		vddrfa1p8-supply = <&vreg_pmu_rfa_1p7>;
	};
};

/* downstream pcie0: vreg-0p9 L5B, vreg-1p2 L10C, perst tlmm 94, wake tlmm 96 */
&pcie0_phy {
	vdda-phy-supply = <&vreg_l5b_0p88>;
	vdda-pll-supply = <&vreg_l10c_1p2>;
	status = "okay";
};

&pm8350_gpios {
	key_vol_down_n: key-vol-down-n-state {
		pins = "gpio6";
		function = PMIC_GPIO_FUNC_NORMAL;
		bias-pull-up;
		input-enable;
		power-source = <1>;
	};

	/* thermistor inputs of the charger NTCs, digital part off */
	usbtemp_l_gpio_default: usbtemp-l-default-state {
		pins = "gpio2";
		function = PMIC_GPIO_FUNC_NORMAL;
		bias-high-impedance;
	};

	usbtemp_r_gpio_default: usbtemp-r-default-state {
		pins = "gpio3";
		function = PMIC_GPIO_FUNC_NORMAL;
		bias-high-impedance;
	};

	subboard_temp_gpio_default: subboard-temp-default-state {
		pins = "gpio5";
		function = PMIC_GPIO_FUNC_NORMAL;
		bias-high-impedance;
	};
};

&pm8350c_flash {
	status = "okay";

	/*
	 * One white LED on channels 1 and 4 (stock led_switch_0, led-mask
	 * 0x09, symmetric). Stock limits per channel: torch 500 mA, flash
	 * 1500 mA for 1280 ms; the torch is kept at 250 mA per channel.
	 */
	led-0 {
		function = LED_FUNCTION_FLASH;
		color = <LED_COLOR_ID_WHITE>;
		led-sources = <1>, <4>;
		led-max-microamp = <500000>;
		flash-max-microamp = <2000000>;
		flash-max-timeout-us = <1280000>;
	};
};

&pm8350c_gpios {
	tx_boost_en_active: tx-boost-en-active-state {
		pins = "gpio4";
		function = PMIC_GPIO_FUNC_NORMAL;
		output-high;
		bias-disable;
		power-source = <1>;
		qcom,drive-strength = <PMIC_GPIO_STRENGTH_MED>;
	};

	tx_boost_en_sleep: tx-boost-en-sleep-state {
		pins = "gpio4";
		function = PMIC_GPIO_FUNC_NORMAL;
		output-low;
		bias-disable;
		power-source = <1>;
		qcom,drive-strength = <PMIC_GPIO_STRENGTH_MED>;
	};

	eusb2_reset_default: eusb2-reset-default-state {
		pins = "gpio7";
		function = PMIC_GPIO_FUNC_NORMAL;
		input-enable;
		output-enable;
		bias-disable;
		power-source = <1>;
		qcom,drive-strength = <PMIC_GPIO_STRENGTH_MED>;
	};

	wrx_ovp_off_active: wrx-ovp-off-active-state {
		pins = "gpio8";
		function = PMIC_GPIO_FUNC_NORMAL;
		output-high;
		bias-disable;
		power-source = <0>;
		qcom,drive-strength = <PMIC_GPIO_STRENGTH_MED>;
	};

	wrx_ovp_off_sleep: wrx-ovp-off-sleep-state {
		pins = "gpio8";
		function = PMIC_GPIO_FUNC_NORMAL;
		output-low;
		bias-disable;
		power-source = <0>;
		qcom,drive-strength = <PMIC_GPIO_STRENGTH_MED>;
	};

	dischg_enable: dischg-enable-state {
		pins = "gpio9";
		function = PMIC_GPIO_FUNC_NORMAL;
		output-high;
		bias-disable;
		power-source = <0>;
		qcom,drive-strength = <PMIC_GPIO_STRENGTH_LOW>;
	};

	dischg_disable: dischg-disable-state {
		pins = "gpio9";
		function = PMIC_GPIO_FUNC_NORMAL;
		output-low;
		bias-disable;
		power-source = <0>;
		qcom,drive-strength = <PMIC_GPIO_STRENGTH_LOW>;
	};
};

&pmk8350_rtc {
	status = "okay";
};

&pmk8350_sdam_2 {
	hap_cl_brake: cl-brake@7c {
		reg = <0x7c 0x1>;
		bits = <0 8>;
	};
};

/*
 * PM8350B HV haptics (LRA), values of the stock qcom,hv-haptics@f000 node;
 * the effects are the pm8350b.dtsi defaults, identical to stock.
 */
&pm8350b_haptics {
	nvmem-cell-names = "hap_cl_brake";
	nvmem-cells = <&hap_cl_brake>;
	nvmem-names = "hap_cfg_sdam";
	nvmem = <&pmk8350_sdam_46>;
	qcom,pbs-client = <&pm8350b_pbs2>;

	qcom,vmax-mv = <1280>;
	qcom,cl-vmax-mv = <1280>;
	qcom,lra-period-us = <5882>;
	qcom,fifo-vmax-mv = <9100>;
	qcom,old-steady-vmax-mv = <9100>;
	qcom,cal-data-restore;
	qcom,vibrator-type = <809>;

	status = "okay";
};

&pmk8350_vadc {
	/*
	 * Charger NTCs. qcom,scale-fn-type 5 (SCALE_HW_CALIB_DEFAULT): the
	 * charger wants the voltage and applies its own NTC table.
	 */
	channel@146 {
		reg = <PM8350_ADC7_AMUX_THM3_100K_PU(1)>;
		label = "pm8350_hot_pocket_therm";
		qcom,ratiometric;
		qcom,hw-settle-time = <200>;
		qcom,pre-scaling = <1 1>;
	};

	channel@14a {
		reg = <PM8350_ADC7_GPIO1_100K_PU(1)>;
		label = "usb_temp_adc";
		qcom,ratiometric;
		qcom,hw-settle-time = <200>;
		qcom,pre-scaling = <1 1>;
		qcom,scale-fn-type = <5>;
	};

	channel@14b {
		reg = <PM8350_ADC7_GPIO2_100K_PU(1)>;
		label = "usb_supplementary_temp_adc";
		qcom,ratiometric;
		qcom,hw-settle-time = <200>;
		qcom,pre-scaling = <1 1>;
		qcom,scale-fn-type = <5>;
	};

	channel@14d {
		reg = <PM8350_ADC7_GPIO4_100K_PU(1)>;
		label = "subboard_temp_adc";
		qcom,ratiometric;
		qcom,hw-settle-time = <200>;
		qcom,pre-scaling = <1 1>;
		qcom,scale-fn-type = <5>;
	};
};

&pon_pwrkey {
	status = "okay";
};

/* on senna RESIN is Volume Up (downstream linux,code = <115>) */
&pon_resin {
	linux,code = <KEY_VOLUMEUP>;
	status = "okay";
};

&qupv3_id_0 {
	status = "okay";
};

&qupv3_id_1 {
	status = "okay";
};

&qupv3_id_2 {
	status = "okay";
};

&gpi_dma2 {
	status = "okay";
};

/* Split images from the modem partition (/vendor/firmware_mnt/image) */
&remoteproc_adsp {
	firmware-name = "qcom/sm8475/realme/senna/adsp.mdt";
	status = "okay";
};

&remoteproc_cdsp {
	firmware-name = "qcom/sm8475/realme/senna/cdsp.mdt";
	/*
	 * Without a DDR vote the CDSP never signals ready once interconnect
	 * sync_state dropped the boot votes (qxm_nsp at 0, start timed out).
	 * Downstream votes "rproc_ddr" (CDSP_PROC -> EBI1); sm8550.dtsi has
	 * the same property in the SoC dtsi.
	 */
	interconnects = <&nsp_noc MASTER_CDSP_PROC QCOM_ICC_TAG_ALWAYS
			 &mc_virt SLAVE_EBI1 QCOM_ICC_TAG_ALWAYS>;
	status = "okay";
};

&remoteproc_mpss {
	firmware-name = "qcom/sm8475/realme/senna/modem.mdt";
	status = "okay";
};

&remoteproc_slpi {
	firmware-name = "qcom/sm8475/realme/senna/slpi.mdt";
	status = "okay";
};

/*
 * IPA 5.1: SoC node from the upstream "SM8450 IPA support" v2 series.
 * GSI firmware is loaded by the AP into ipa_gsi_mem, as downstream does
 * (ipa_hw memory-regions, pas-id 15).
 */
&ipa {
	qcom,gsi-loader = "self";
	memory-region = <&ipa_gsi_mem>;
	firmware-name = "qcom/sm8475/realme/senna/ipa_fws.mdt";
	status = "okay";
};

/* downstream qupv3_se4_spi: synaptics_tcm@0, compatible "synaptics-s3910" */
&spi4 {
	status = "okay";

	touchscreen@0 {
		compatible = "syna,s3910";
		reg = <0>;
		spi-max-frequency = <12000000>;

		interrupts-extended = <&tlmm 21 IRQ_TYPE_LEVEL_LOW>;
		reset-gpios = <&tlmm 20 GPIO_ACTIVE_LOW>;

		vdd-supply = <&vreg_l3c_3p0>;
		vcc-supply = <&ts_vcc_1p8>;

		pinctrl-0 = <&ts_int_default>, <&ts_reset_default>;
		pinctrl-names = "default";
	};
};

&tlmm {
	/* qcom,gpios-reserved in the downstream tree */
	gpio-reserved-ranges = <28 4>, <36 4>;

	lcd_reset_n_active: lcd-reset-n-active-state {
		pins = "gpio3";
		function = "gpio";
		drive-strength = <8>;
		bias-disable;
	};

	lcd_reset_n_suspend: lcd-reset-n-suspend-state {
		pins = "gpio3";
		function = "gpio";
		drive-strength = <2>;
		bias-pull-down;
	};

	iris_reset_active: iris-reset-active-state {
		pins = "gpio44";
		function = "gpio";
		drive-strength = <8>;
		bias-disable;
	};

	iris_reset_suspend: iris-reset-suspend-state {
		pins = "gpio44";
		function = "gpio";
		drive-strength = <2>;
		bias-pull-down;
	};

	iris_wakeup_active: iris-wakeup-active-state {
		pins = "gpio54";
		function = "gpio";
		drive-strength = <8>;
		bias-disable;
	};

	iris_wakeup_suspend: iris-wakeup-suspend-state {
		pins = "gpio54";
		function = "gpio";
		drive-strength = <2>;
		bias-pull-down;
	};

	mdp_vsync_active: mdp-vsync-active-state {
		pins = "gpio86";
		function = "mdp_vsync";
		drive-strength = <2>;
		bias-pull-down;
	};

	mdp_vsync_suspend: mdp-vsync-suspend-state {
		pins = "gpio86";
		function = "mdp_vsync";
		drive-strength = <2>;
		bias-pull-down;
	};

	iris_vdd_default: iris-vdd-default-state {
		pins = "gpio182";
		function = "gpio";
		drive-strength = <8>;
		bias-pull-up;
	};

	cam_main_mclk_default: cam-main-mclk-default-state {
		pins = "gpio101";
		function = "cam_mclk";
		drive-strength = <6>;
		bias-disable;
	};

	cam_main_reset_default: cam-main-reset-default-state {
		pins = "gpio120";
		function = "gpio";
		drive-strength = <2>;
		bias-disable;
	};

	cam_uw_mclk_default: cam-uw-mclk-default-state {
		pins = "gpio102";
		function = "cam_mclk";
		drive-strength = <4>;
		bias-disable;
	};

	cam_uw_reset_default: cam-uw-reset-default-state {
		pins = "gpio24";
		function = "gpio";
		drive-strength = <2>;
		bias-disable;
	};

	ts_reset_default: ts-reset-default-state {
		pins = "gpio20";
		function = "gpio";
		drive-strength = <8>;
		bias-disable;
	};

	ts_int_default: ts-int-default-state {
		pins = "gpio21";
		function = "gpio";
		drive-strength = <2>;
		bias-pull-up;
	};

	/*
	 * WCN6855 XO_CLK select (downstream qcom,xo-clk-gpio = tlmm 204 in the
	 * cnss-qca6490 and bt_qca6490 nodes). The stock kernels take it from the
	 * eGPIO island and drive it low (5.10 dump: out low, func0, pull down);
	 * left as eGPIO it is not driven by APPS at all.
	 */
	wcn_xo_clk_default: wcn-xo-clk-default-state {
		pins = "gpio204";
		function = "gpio";
		drive-strength = <2>;
		bias-pull-down;
		output-low;
	};

	/* downstream cnss_wlan_en_active */
	wlan_en_default: wlan-en-default-state {
		pins = "gpio80";
		function = "gpio";
		drive-strength = <16>;
		bias-pull-up;
		output-high;
	};

	bt_en_default: bt-en-default-state {
		pins = "gpio81";
		function = "gpio";
		drive-strength = <2>;
		bias-pull-down;
	};

	ts_vcc_en_default: ts-vcc-en-default-state {
		pins = "gpio97";
		function = "gpio";
		drive-strength = <2>;
		bias-disable;
	};

	/* charger: OTG boost and OVP switches, reverse wireless OVP */
	otg_ovp_en_active: otg-ovp-en-active-state {
		pins = "gpio57";
		function = "gpio";
		drive-strength = <2>;
		bias-pull-up;
		output-high;
	};

	otg_ovp_en_sleep: otg-ovp-en-sleep-state {
		pins = "gpio57";
		function = "gpio";
		drive-strength = <2>;
		bias-pull-down;
		output-low;
	};

	otg_booster_en_active: otg-booster-en-active-state {
		pins = "gpio64";
		function = "gpio";
		drive-strength = <2>;
		bias-pull-up;
		output-high;
	};

	otg_booster_en_sleep: otg-booster-en-sleep-state {
		pins = "gpio64";
		function = "gpio";
		drive-strength = <2>;
		bias-pull-down;
		output-low;
	};

	tx_ovp_en_active: tx-ovp-en-active-state {
		pins = "gpio126";
		function = "gpio";
		drive-strength = <2>;
		bias-disable;
		output-high;
	};

	tx_ovp_en_sleep: tx-ovp-en-sleep-state {
		pins = "gpio126";
		function = "gpio";
		drive-strength = <2>;
		bias-disable;
		output-low;
	};
};

&uart20 {
	status = "okay";

	bluetooth {
		compatible = "qcom,wcn6855-bt";

		vddrfacmn-supply = <&vreg_pmu_rfa_cmn_0p8>;
		vddaon-supply = <&vreg_pmu_aon_0p8>;
		vddwlcx-supply = <&vreg_pmu_wlcx_0p8>;
		vddwlmx-supply = <&vreg_pmu_wlmx_0p8>;
		vddbtcmx-supply = <&vreg_pmu_btcmx_0p8>;
		vddrfa0p8-supply = <&vreg_pmu_rfa_0p8>;
		vddrfa1p2-supply = <&vreg_pmu_rfa_1p2>;
		vddrfa1p8-supply = <&vreg_pmu_rfa_1p7>;

		max-speed = <3200000>;
	};
};

&ufs_mem_hc {
	reset-gpios = <&tlmm 210 GPIO_ACTIVE_LOW>;

	vcc-supply = <&vreg_l7b_2p5>;
	vcc-max-microamp = <1100000>;
	vccq-supply = <&vreg_l9b_1p2>;
	vccq-max-microamp = <1200000>;

	status = "okay";
};

&ufs_mem_phy {
	vdda-phy-supply = <&vreg_l5b_0p88>;
	vdda-pll-supply = <&vreg_l10c_1p2>;

	status = "okay";
};

/* USB 2.0 only, the role follows the USB-C port (UCSI over pmic-glink) */
&usb_1 {
	qcom,select-utmi-as-pipe-clk;
	maximum-speed = "high-speed";
	phys = <&usb_1_hsphy>;
	phy-names = "usb2-phy";
	status = "okay";
};

&usb_1_dwc3_hs {
	remote-endpoint = <&pmic_glink_hs_in>;
};

&usb_1_hsphy {
	vdd-supply = <&vreg_l5b_0p88>;
	vdda12-supply = <&vreg_l10c_1p2>;

	phys = <&eusb2_repeater>;

	status = "okay";
};

&i2c13 {
	clock-frequency = <400000>;
	status = "okay";

	/*
	 * TFA9873 N1B (revision 0x0b73), reset active high (NXP: 1, 5 ms, 0),
	 * supply S10B.
	 * slot 0 / left channel = top earpiece, slot 1 / right = bottom
	 * loudspeaker (measured).
	 * Tuning: the bitfields of the stock tuning container
	 * (odm/firmware/tfa98xx.cnt, "Realme 9873N1B"), device lists and the
	 * "speaker"/"receiver" profiles. The TDM fields are left out: they
	 * describe the 32 bit, current sensing link of the stock firmware.
	 */
	spk_amp_l: amplifier@34 {
		compatible = "nxp,tfa9874";
		reg = <0x34>;
		reset-gpios = <&tlmm 50 GPIO_ACTIVE_HIGH>;
		vdd-supply = <&vreg_s10b_1p8>;
		nxp,tdm-slot = <0>;
		sound-name-prefix = "Speaker Left";
		#sound-dai-cells = <0>;

		/* ENCURCOMP, OCP reference scaling (amp, boost), adaptive
		 * boost trip levels, 2nd boost voltage, max coil current,
		 * boost slope */
		nxp,init-bitfields = <0x6f50 0x0>, <0x54a1 0x3>, <0x7371 0x3>,
				     <0x7444 0xb>, <0x7584 0x10>, <0x7695 0x2e>,
				     <0x7003 0x8>, <0x71c1 0x1>;
		/* DCA, LNMODE, INPLEV, TDMSPKG, PWMFREQ */
		nxp,speaker-bitfields = <0x0040 0x1>, <0x62e1 0x0>, <0x0240 0x0>,
					<0x5f63 0x6>, <0x5900 0x1>;
		/* earpiece: no boost, low noise mode, attenuated input */
		nxp,receiver-bitfields = <0x0040 0x0>, <0x62e1 0x3>, <0x0240 0x1>,
					 <0x5f63 0xf>, <0x5900 0x0>;
	};

	spk_amp_r: amplifier@35 {
		compatible = "nxp,tfa9874";
		reg = <0x35>;
		reset-gpios = <&tlmm 51 GPIO_ACTIVE_HIGH>;
		vdd-supply = <&vreg_s10b_1p8>;
		nxp,tdm-slot = <1>;
		sound-name-prefix = "Speaker Right";
		#sound-dai-cells = <0>;

		nxp,init-bitfields = <0x6f50 0x0>, <0x54a1 0x3>, <0x7371 0x3>,
				     <0x7444 0xb>, <0x7584 0x10>, <0x7695 0x2e>,
				     <0x7003 0xa>, <0x71c1 0x1>;
		nxp,speaker-bitfields = <0x0040 0x1>, <0x62e1 0x0>, <0x0240 0x0>,
					<0x5f63 0x6>, <0x5900 0x1>;
	};
};

&q6apmbedai {
	#address-cells = <1>;
	#size-cells = <0>;

	dai@TERTIARY_MI2S_RX {
		reg = <TERTIARY_MI2S_RX>;
		clocks = <&q6prmcc LPASS_CLK_ID_TER_MI2S_IBIT LPASS_CLK_ATTRIBUTE_COUPLE_NO>;
		clock-names = "bclk";
	};
};

/* WCD9385 slaves: same SoundWire layout as sm8450-hdk / downstream waipio */
&swr1 {
	status = "okay";

	wcd_rx: codec@0,4 {
		compatible = "sdw20217010d00";
		reg = <0 4>;
		qcom,rx-port-mapping = <1 2 3 4 5>;
	};
};

&swr2 {
	status = "okay";

	wcd_tx: codec@0,3 {
		compatible = "sdw20217010d00";
		reg = <0 3>;
		qcom,tx-port-mapping = <1 1 2 3>;
	};
};

/* provides the fsgen clock rx/tx macros need; no DMICs on senna */
&vamacro {
	vdd-micb-supply = <&vreg_s10b_1p8>;
	qcom,dmic-sample-rate = <600000>;

	status = "okay";
};

&tlmm {
	wcd_default: wcd-reset-n-active-state {
		pins = "gpio43";
		function = "gpio";
		drive-strength = <16>;
		bias-disable;
		output-low;
	};

	/* downstream tert_mi2s_{sck,sd0,ws,sd1}_active */
	tert_mi2s_active: tert-mi2s-active-state {
		sck-pins {
			pins = "gpio121";
			function = "mi2s2_sck";
			drive-strength = <8>;
			bias-disable;
		};

		data0-pins {
			pins = "gpio122";
			function = "mi2s2_data0";
			drive-strength = <8>;
			bias-disable;
		};

		ws-pins {
			pins = "gpio123";
			function = "mi2s2_ws";
			drive-strength = <8>;
			bias-disable;
		};

		data1-pins {
			pins = "gpio124";
			function = "mi2s2_data1";
			drive-strength = <8>;
			bias-pull-down;
		};
	};
};
